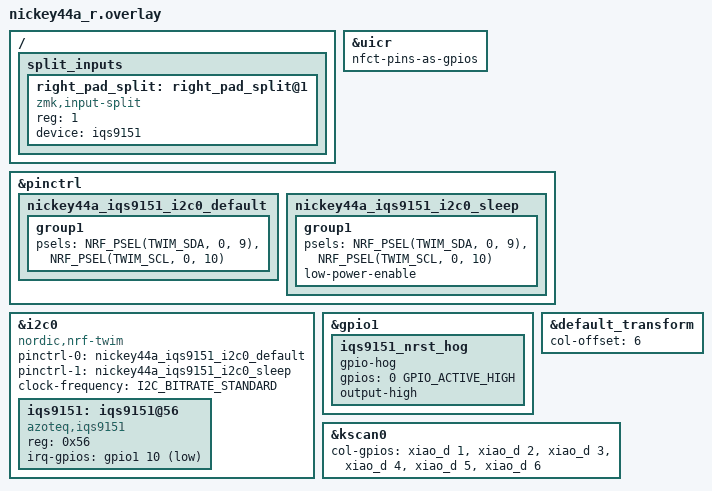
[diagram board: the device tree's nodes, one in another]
#include "nickey44a.dtsi"
#include <dt-bindings/pinctrl/nrf-pinctrl.h>

/*
 * Right pad: LalaPad Gen2 trackpad (Azoteq IQS9151, I2C 0x56) on the former
 * TPS43 FPC breakout wiring:
 *   SDA  = XIAO NFC1/P0.09
 *   SCL  = XIAO NFC2/P0.10
 *   RDY  = XIAO P1.10 (IQS9151 RDY, active low)
 *   NRST = XIAO P1.00 (held high; leave unconnected if the module has none)
 * The left pad is also an IQS9151 (see nickey44a_l.overlay).
 */

&uicr {
    nfct-pins-as-gpios;
};

&pinctrl {
    nickey44a_iqs9151_i2c0_default: nickey44a_iqs9151_i2c0_default {
        group1 {
            psels = <NRF_PSEL(TWIM_SDA, 0, 9)>,
                    <NRF_PSEL(TWIM_SCL, 0, 10)>;
        };
    };

    nickey44a_iqs9151_i2c0_sleep: nickey44a_iqs9151_i2c0_sleep {
        group1 {
            psels = <NRF_PSEL(TWIM_SDA, 0, 9)>,
                    <NRF_PSEL(TWIM_SCL, 0, 10)>;
            low-power-enable;
        };
    };
};

/*
 * nemu-link: this half is a 2.4GHz peripheral (PERIPHERAL_ID 1). The pad's
 * raw events are forwarded to the dongle as input-split reg 1; every
 * listener / input processor (scaling, gestures, scroll snap) runs on the
 * dongle (boards/extensions/nemu-link-dongle/nemu-link-dongle.overlay).
 */
/ {
    split_inputs {
        #address-cells = <1>;
        #size-cells = <0>;

        right_pad_split: right_pad_split@1 {
            compatible = "zmk,input-split";
            reg = <1>;
            device = <&iqs9151>;
        };
    };
};

&i2c0 {
    status = "okay";
    compatible = "nordic,nrf-twim";
    pinctrl-0 = <&nickey44a_iqs9151_i2c0_default>;
    pinctrl-1 = <&nickey44a_iqs9151_i2c0_sleep>;
    pinctrl-names = "default", "sleep";
    clock-frequency = <I2C_BITRATE_STANDARD>;
    #address-cells = <1>;
    #size-cells = <0>;

    iqs9151: iqs9151@56 {
        compatible = "azoteq,iqs9151";
        reg = <0x56>;
        status = "okay";
        /* IQS9151 RDY on the former TPS43 RDY line (P1.10). */
        irq-gpios = <&gpio1 10 (GPIO_ACTIVE_LOW | GPIO_PULL_UP)>;
    };
};

/*
 * The former TPS43 NRST line (P1.00) is driven high so an IQS9151 module
 * with NRST wired to it is never held in reset.
 */
&gpio1 {
    iqs9151_nrst_hog {
        gpio-hog;
        gpios = <0 GPIO_ACTIVE_HIGH>;
        output-high;
    };
};

&default_transform {
    col-offset = <6>;
};

&kscan0 {
        col-gpios
            = <&xiao_d 1 GPIO_ACTIVE_HIGH>
            , <&xiao_d 2 GPIO_ACTIVE_HIGH>
            , <&xiao_d 3 GPIO_ACTIVE_HIGH>
            , <&xiao_d 4 GPIO_ACTIVE_HIGH>
            , <&xiao_d 5 GPIO_ACTIVE_HIGH>
            , <&xiao_d 6 GPIO_ACTIVE_HIGH>
            ;
};

/* No haptics on the right: the DRV2605L / VG0825001U board was removed. */
